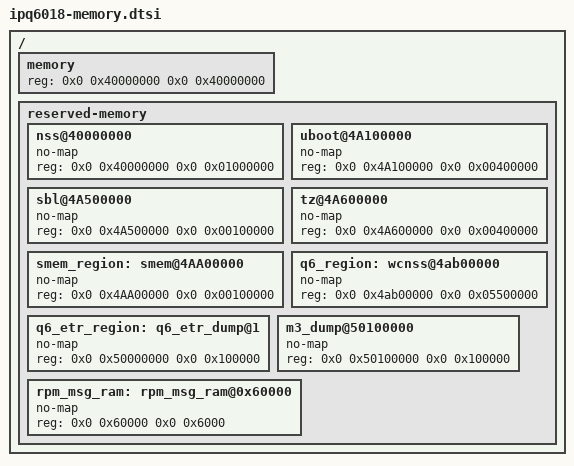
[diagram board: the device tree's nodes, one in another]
/*
 * Copyright (c) 2018-2020, The Linux Foundation. All rights reserved.
 *
 * Permission to use, copy, modify, and/or distribute this software for any
 * purpose with or without fee is hereby granted, provided that the above
 * copyright notice and this permission notice appear in all copies.
 *
 * THE SOFTWARE IS PROVIDED "AS IS" AND THE AUTHOR DISCLAIMS ALL WARRANTIES
 * WITH REGARD TO THIS SOFTWARE INCLUDING ALL IMPLIED WARRANTIES OF
 * MERCHANTABILITY AND FITNESS. IN NO EVENT SHALL THE AUTHOR BE LIABLE FOR
 * ANY SPECIAL, DIRECT, INDIRECT, OR CONSEQUENTIAL DAMAGES OR ANY DAMAGES
 * WHATSOEVER RESULTING FROM LOSS OF USE, DATA OR PROFITS, WHETHER IN AN
 * ACTION OF CONTRACT, NEGLIGENCE OR OTHER TORTIOUS ACTION, ARISING OUT OF
 * OR IN CONNECTION WITH THE USE OR PERFORMANCE OF THIS SOFTWARE.
 */


/ {

	/*		  Default Profile
	 * +=========+==============+========================+
	 * |        |              |                         |
	 * | Region | Start Offset |          Size           |
	 * |        |              |                         |
	 * +--------+--------------+-------------------------+
	 * |        |              |                         |
	 * |  NSS   |  0x40000000  |          16MB           |
	 * |        |              |                         |
	 * +--------+--------------+-------------------------+
	 * |        |              |                         |
	 * |        |              |                         |
	 * |        |              |                         |
	 * |        |              |                         |
	 * | Linux  |  0x41000000  |         145MB           |
	 * |        |              |                         |
	 * |        |              |                         |
	 * |        |              |                         |
	 * +--------+--------------+-------------------------+
	 * |        |              |                         |
	 * | uboot  |  0x4A100000  |           4MB           |
	 * |        |              |                         |
	 * +--------+--------------+-------------------------+
	 * |  SBL   |  0x4A500000  |           1MB           |
	 * +--------+--------------+-------------------------+
	 * |        |              |                         |
	 * | TZ+HYP |  0x4A600000  |           4MB           |
	 * |        |              |                         |
	 * +--------+--------------+-------------------------+
	 * |  smem  |  0x4AA00000  |           1MB           |
	 * +--------+--------------+-------------------------+
	 * |        |              |                         |
	 * |        |              |                         |
	 * | WLAN   |              |                         |
	 * |   Q6   |  0x4AB00000  |          85MB           |
	 * |        |              |                         |
	 * |        |              |                         |
	 * +--------+--------------+-------------------------+
	 * | WLAN   |              |                         |
	 * | Q6 ETR |  0x50000000  |           1MB           |
	 * | Region |              |                         |
	 * +--------+--------------+-------------------------+
	 * | M3 Dump|  0x50100000  |           1MB           |
	 * +--------+--------------+-------------------------+
	 * |        |              |                         |
	 * |  Pine  |  0x50200000  |          55MB           |
	 * |        |              |  (on CP01-C3 RDP only)  |
	 * +=================================================+
	 * |                                                 |
	 * |                                                 |
	 * |                                                 |
	 * |            766MB memory for Linux               |
	 * |                                                 |
	 * |                                                 |
	 * |                                                 |
	 * +=================================================+
	 */

	memory {
		device_type = "memory";
		reg = <0x0 0x40000000 0x0 0x40000000>;
	};

	reserved-memory {
		#address-cells = <2>;
		#size-cells = <2>;
		ranges;

		nss@40000000 {
			no-map;
			reg = <0x0 0x40000000 0x0 0x01000000>;
		};

		uboot@4A100000 {
			no-map;
			reg = <0x0 0x4A100000 0x0 0x00400000>;
		};

		sbl@4A500000 {
			no-map;
			reg = <0x0 0x4A500000 0x0 0x00100000>;
		};

		tz@4A600000 {
			no-map;
			reg = <0x0 0x4A600000 0x0 0x00400000>;
		};

		smem_region: smem@4AA00000 {
			no-map;
			reg = <0x0 0x4AA00000 0x0 0x00100000>;
		};

		q6_region: wcnss@4ab00000 {
			no-map;
			reg = <0x0 0x4ab00000 0x0 0x05500000>;
		};

		q6_etr_region: q6_etr_dump@1 {
			no-map;
			reg = <0x0 0x50000000 0x0 0x100000>;
		};

		m3_dump@50100000 {
			no-map;
			reg = <0x0 0x50100000 0x0 0x100000>;
		};

		rpm_msg_ram: rpm_msg_ram@0x60000 {
			no-map;
			reg = <0x0 0x60000 0x0 0x6000>;
		};
	};
};
